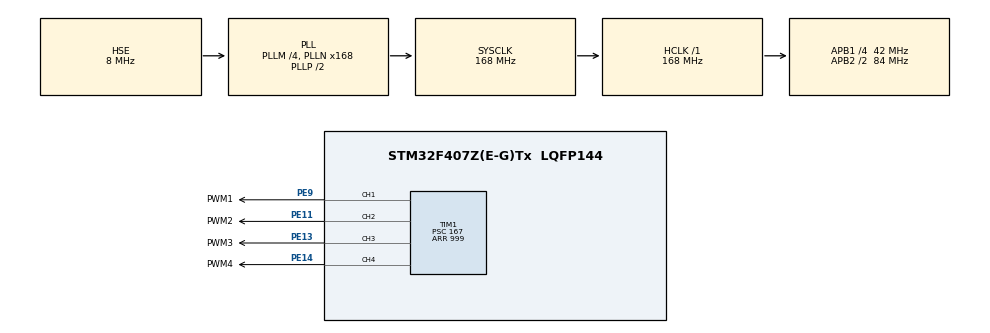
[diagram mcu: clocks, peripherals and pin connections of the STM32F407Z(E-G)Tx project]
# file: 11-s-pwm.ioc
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Dma.Request0=TIM1_CH1
Dma.Request1=TIM1_CH2
Dma.Request2=TIM1_CH3
Dma.TIM1_CH1.0.Direction=DMA_MEMORY_TO_PERIPH
Dma.TIM1_CH1.0.FIFOMode=DMA_FIFOMODE_DISABLE
Dma.TIM1_CH1.0.Instance=DMA2_Stream1
Dma.TIM1_CH1.0.MemDataAlignment=DMA_MDATAALIGN_HALFWORD
Dma.TIM1_CH1.0.MemInc=DMA_MINC_ENABLE
Dma.TIM1_CH1.0.Mode=DMA_CIRCULAR
Dma.TIM1_CH1.0.PeriphDataAlignment=DMA_PDATAALIGN_HALFWORD
Dma.TIM1_CH1.0.PeriphInc=DMA_PINC_DISABLE
Dma.TIM1_CH1.0.Priority=DMA_PRIORITY_LOW
Dma.TIM1_CH2.1.Direction=DMA_MEMORY_TO_PERIPH
Dma.TIM1_CH2.1.FIFOMode=DMA_FIFOMODE_DISABLE
Dma.TIM1_CH2.1.Instance=DMA2_Stream2
Dma.TIM1_CH2.1.MemDataAlignment=DMA_MDATAALIGN_HALFWORD
Dma.TIM1_CH2.1.MemInc=DMA_MINC_ENABLE
Dma.TIM1_CH2.1.Mode=DMA_CIRCULAR
Dma.TIM1_CH2.1.PeriphDataAlignment=DMA_PDATAALIGN_HALFWORD
Dma.TIM1_CH2.1.PeriphInc=DMA_PINC_DISABLE
Dma.TIM1_CH2.1.Priority=DMA_PRIORITY_LOW
Dma.TIM1_CH3.2.Direction=DMA_MEMORY_TO_PERIPH
Dma.TIM1_CH3.2.FIFOMode=DMA_FIFOMODE_DISABLE
Dma.TIM1_CH3.2.Instance=DMA2_Stream6
Dma.TIM1_CH3.2.MemDataAlignment=DMA_MDATAALIGN_HALFWORD
Dma.TIM1_CH3.2.MemInc=DMA_MINC_ENABLE
Dma.TIM1_CH3.2.Mode=DMA_CIRCULAR
Dma.TIM1_CH3.2.PeriphDataAlignment=DMA_PDATAALIGN_HALFWORD
Dma.TIM1_CH3.2.PeriphInc=DMA_PINC_DISABLE
Dma.TIM1_CH3.2.Priority=DMA_PRIORITY_LOW
Mcu.Family=STM32F4
Mcu.Name=STM32F407Z(E-G)Tx
Mcu.Package=LQFP144
NVIC.DMA2_Stream1_IRQn=true\:0\:0\:false\:false\:true\:false\:true\:true
NVIC.DMA2_Stream2_IRQn=true\:0\:0\:false\:false\:true\:false\:true\:true
NVIC.DMA2_Stream6_IRQn=true\:0\:0\:false\:false\:true\:false\:true\:true
NVIC.PriorityGroup=NVIC_PRIORITYGROUP_4
PA13.Mode=Serial_Wire
PA13.Signal=SYS_JTMS-SWDIO
PA14.Mode=Serial_Wire
PA14.Signal=SYS_JTCK-SWCLK
PC14-OSC32_IN.Mode=LSE-External-Oscillator
PC14-OSC32_IN.Signal=RCC_OSC32_IN
PC15-OSC32_OUT.Mode=LSE-External-Oscillator
PC15-OSC32_OUT.Signal=RCC_OSC32_OUT
PE11.GPIO_Label=PWM2
PE11.Signal=S_TIM1_CH2
PE13.GPIO_Label=PWM3
PE13.Signal=S_TIM1_CH3
PE14.GPIO_Label=PWM4
PE14.Signal=S_TIM1_CH4
PE9.GPIO_Label=PWM1
PE9.Signal=S_TIM1_CH1
PH0-OSC_IN.Mode=HSE-External-Oscillator
PH0-OSC_IN.Signal=RCC_OSC_IN
PH1-OSC_OUT.Mode=HSE-External-Oscillator
PH1-OSC_OUT.Signal=RCC_OSC_OUT
ProjectManager.HeapSize=0x200
ProjectManager.StackSize=0x400
ProjectManager.TargetToolchain=STM32CubeIDE
RCC.48MHZClocksFreq_Value=84000000
RCC.AHBFreq_Value=168000000
RCC.APB1CLKDivider=RCC_HCLK_DIV4
RCC.APB1Freq_Value=42000000
RCC.APB1TimFreq_Value=84000000
RCC.APB2CLKDivider=RCC_HCLK_DIV2
RCC.APB2Freq_Value=84000000
RCC.APB2TimFreq_Value=168000000
RCC.CortexFreq_Value=168000000
RCC.HCLKFreq_Value=168000000
RCC.HSE_VALUE=8000000
RCC.HSI_VALUE=16000000
RCC.PLLM=4
RCC.PLLN=168
RCC.PLLSourceVirtual=RCC_PLLSOURCE_HSE
RCC.SYSCLKFreq_VALUE=168000000
RCC.SYSCLKSource=RCC_SYSCLKSOURCE_PLLCLK
RCC.VCOOutputFreq_Value=336000000
SH.S_TIM1_CH1.0=TIM1_CH1,Output Compare1 CH1
SH.S_TIM1_CH2.0=TIM1_CH2,Output Compare2 CH2
SH.S_TIM1_CH3.0=TIM1_CH3,Output Compare3 CH3
SH.S_TIM1_CH4.0=TIM1_CH4,PWM Generation4 CH4
TIM1.AutoReloadPreload=TIM_AUTORELOAD_PRELOAD_ENABLE
TIM1.Channel-Output\ Compare1\ CH1=TIM_CHANNEL_1
TIM1.Channel-Output\ Compare2\ CH2=TIM_CHANNEL_2
TIM1.Channel-Output\ Compare3\ CH3=TIM_CHANNEL_3
TIM1.Channel-PWM\ Generation4\ CH4=TIM_CHANNEL_4
TIM1.OC1Preload=DISABLE
TIM1.OCMode_1=TIM_OCMODE_TOGGLE
TIM1.OCMode_2=TIM_OCMODE_TOGGLE
TIM1.OCMode_3=TIM_OCMODE_TOGGLE
TIM1.OCMode_PWM-PWM\ Generation4\ CH4=TIM_OCMODE_PWM2
TIM1.Period=999
TIM1.Prescaler=167
TIM1.Pulse-Output\ Compare2\ CH2=0
TIM1.Pulse-Output\ Compare3\ CH3=0
TIM1.Pulse-PWM\ Generation4\ CH4=500
VP_TIM1_VS_ClockSourceINT.Mode=Internal
board=custom

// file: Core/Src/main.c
/* USER CODE BEGIN Header */
/**
  ******************************************************************************
  * @file           : main.c
  * @brief          : Main program body
  ******************************************************************************
  * @attention
  *
  * Copyright (c) 2023 STMicroelectronics.
  * All rights reserved.
  *
  * This software is licensed under terms that can be found in the LICENSE file
  * in the root directory of this software component.
  * If no LICENSE file comes with this software, it is provided AS-IS.
  *
  ******************************************************************************
  */
/* USER CODE END Header */
#include "main.h"
#include "dma.h"
#include "tim.h"
#include "gpio.h"

/* USER CODE BEGIN PV */

//https://shequ.stmicroelectronics.cn/thread-620967-1-1.html
//左边下降沿，右边上升沿
uint16_t Data1_to_Comp[] = {31, 0}; //ch1
uint16_t Data2_to_Comp[] = {700, 300}; //ch2
uint16_t Data3_to_Comp[] = {400, 100}; //ch3
extern DMA_HandleTypeDef hdma_tim1_ch1;
extern DMA_HandleTypeDef hdma_tim1_ch2;
extern DMA_HandleTypeDef hdma_tim1_ch3;

uint16_t test = 0;

/* USER CODE END PV */

void SystemClock_Config(void);

int main(void) {

    /* MCU Configuration--------------------------------------------------------*/

    /* Reset of all peripherals, Initializes the Flash interface and the Systick. */
    HAL_Init();

    /* Configure the system clock */
    SystemClock_Config();

    /* Initialize all configured peripherals */
    MX_GPIO_Init();
    MX_DMA_Init();
    MX_TIM1_Init();
    /* USER CODE BEGIN 2 */

    /*
    // 1 开启TIM1通道1/2/3的比较输出功能
    TIM_CCxChannelCmd(TIM1, TIM_CHANNEL_1, TIM_CCx_ENABLE);
    TIM_CCxChannelCmd(TIM1, TIM_CHANNEL_2, TIM_CCx_ENABLE);
    TIM_CCxChannelCmd(TIM1, TIM_CHANNEL_3, TIM_CCx_ENABLE);

    //2 允许相应通道比较事件的DMA请求并开启相应通道的DMA传输功能
    hdma_tim1_ch1.State = HAL_DMA_STATE_READY;
    HAL_DMA_Start_IT(&hdma_tim1_ch1, (uint32_t) Data1_to_Comp, (uint32_t) &TIM1->CCR1, 2);
    __HAL_TIM_ENABLE_DMA(&htim1, TIM_DMA_CC1);

    hdma_tim1_ch2.State = HAL_DMA_STATE_READY;
    HAL_DMA_Start_IT(&hdma_tim1_ch2, (uint32_t) Data2_to_Comp, (uint32_t) &TIM1->CCR2, 2);
    __HAL_TIM_ENABLE_DMA(&htim1, TIM_DMA_CC2);

    hdma_tim1_ch3.State = HAL_DMA_STATE_READY;
    HAL_DMA_Start_IT(&hdma_tim1_ch3, (uint32_t) Data3_to_Comp, (uint32_t) &TIM1->CCR3, 2);
    __HAL_TIM_ENABLE_DMA(&htim1, TIM_DMA_CC3);
    */
    //上面代码等效于：

    HAL_TIM_OC_Start_DMA(&htim1, TIM_CHANNEL_1, (uint32_t *) Data1_to_Comp, 2);
    HAL_TIM_OC_Start_DMA(&htim1, TIM_CHANNEL_2, (uint32_t *) Data2_to_Comp, 2);
    HAL_TIM_OC_Start_DMA(&htim1, TIM_CHANNEL_3, (uint32_t *) Data3_to_Comp, 2);

    //3 使能TIM1通道4的PWM输出功能并使能TIM1,  启动计数器计数。
    HAL_TIM_PWM_Start(&htim1, TIM_CHANNEL_4);

    /* USER CODE END 2 */

    /* Infinite loop */
    while (1) {

    }
}

void SystemClock_Config(void) {
    RCC_OscInitTypeDef RCC_OscInitStruct = {0};
    RCC_ClkInitTypeDef RCC_ClkInitStruct = {0};

    /** Configure the main internal regulator output voltage
    */
    __HAL_RCC_PWR_CLK_ENABLE();
    __HAL_PWR_VOLTAGESCALING_CONFIG(PWR_REGULATOR_VOLTAGE_SCALE1);

    /** Initializes the RCC Oscillators according to the specified parameters
    * in the RCC_OscInitTypeDef structure.
    */
    RCC_OscInitStruct.OscillatorType = RCC_OSCILLATORTYPE_HSE;
    RCC_OscInitStruct.HSEState = RCC_HSE_ON;
    RCC_OscInitStruct.PLL.PLLState = RCC_PLL_ON;
    RCC_OscInitStruct.PLL.PLLSource = RCC_PLLSOURCE_HSE;
    RCC_OscInitStruct.PLL.PLLM = 4;
    RCC_OscInitStruct.PLL.PLLN = 168;
    RCC_OscInitStruct.PLL.PLLP = RCC_PLLP_DIV2;
    RCC_OscInitStruct.PLL.PLLQ = 4;
    if (HAL_RCC_OscConfig(&RCC_OscInitStruct) != HAL_OK) {
        Error_Handler();
    }

    /** Initializes the CPU, AHB and APB buses clocks
    */
    RCC_ClkInitStruct.ClockType = RCC_CLOCKTYPE_HCLK | RCC_CLOCKTYPE_SYSCLK
                                  | RCC_CLOCKTYPE_PCLK1 | RCC_CLOCKTYPE_PCLK2;
    RCC_ClkInitStruct.SYSCLKSource = RCC_SYSCLKSOURCE_PLLCLK;
    RCC_ClkInitStruct.AHBCLKDivider = RCC_SYSCLK_DIV1;
    RCC_ClkInitStruct.APB1CLKDivider = RCC_HCLK_DIV4;
    RCC_ClkInitStruct.APB2CLKDivider = RCC_HCLK_DIV2;

    if (HAL_RCC_ClockConfig(&RCC_ClkInitStruct, FLASH_LATENCY_5) != HAL_OK) {
        Error_Handler();
    }
}

void Error_Handler(void) {
    __disable_irq();
    while (1) {
    }
}
